AUTOSAR XML (schema 4-2-2)
package /ComponentTypes
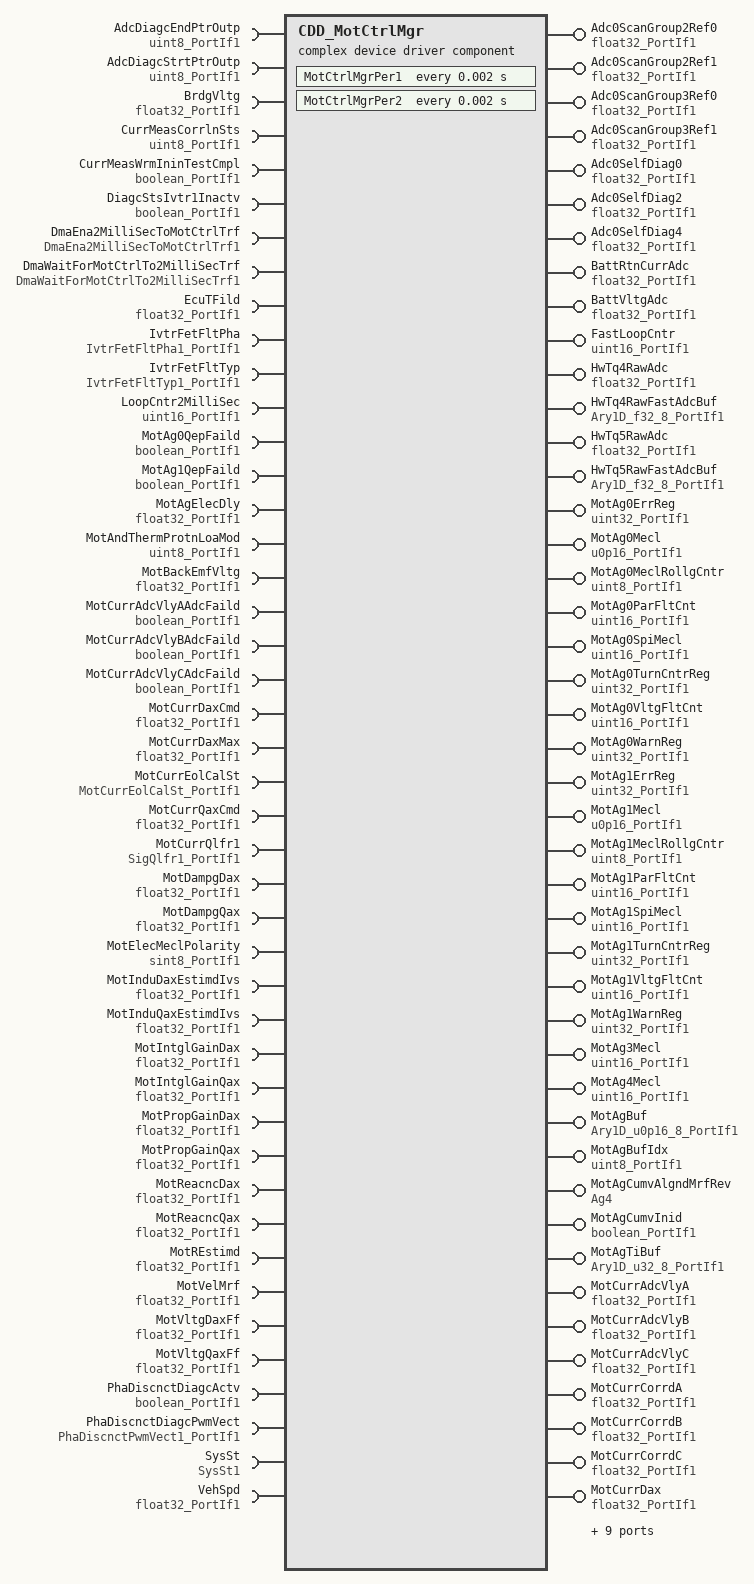
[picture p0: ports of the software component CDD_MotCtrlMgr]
  complex device driver sw component type CDD_MotCtrlMgr
    53 x provide port:
      Adc0ScanGroup2Ref0: nonqueued-sender-com-spec{data-element=Val, init-value=0}, provided-interface=float32_PortIf1
      Adc0ScanGroup2Ref1: nonqueued-sender-com-spec{data-element=Val, init-value=0}, provided-interface=float32_PortIf1
      Adc0ScanGroup3Ref0: nonqueued-sender-com-spec{data-element=Val, init-value=0}, provided-interface=float32_PortIf1
      Adc0ScanGroup3Ref1: nonqueued-sender-com-spec{data-element=Val, init-value=0}, provided-interface=float32_PortIf1
      Adc0SelfDiag0: nonqueued-sender-com-spec{data-element=Val, init-value=0}, provided-interface=float32_PortIf1
      Adc0SelfDiag2: nonqueued-sender-com-spec{data-element=Val, init-value=0}, provided-interface=float32_PortIf1
      Adc0SelfDiag4: nonqueued-sender-com-spec{data-element=Val, init-value=0}, provided-interface=float32_PortIf1
      BattRtnCurrAdc: nonqueued-sender-com-spec{data-element=Val, init-value=0}, provided-interface=float32_PortIf1
      BattVltgAdc: nonqueued-sender-com-spec{data-element=Val, init-value=0}, provided-interface=float32_PortIf1
      FastLoopCntr: nonqueued-sender-com-spec{data-element=Val, init-value=0}, provided-interface=uint16_PortIf1
      HwTq4RawAdc: nonqueued-sender-com-spec{data-element=Val, init-value=0}, provided-interface=float32_PortIf1
      HwTq4RawFastAdcBuf: nonqueued-sender-com-spec{data-element=Ary1D, init-value=8 x 0}, provided-interface=Ary1D_f32_8_PortIf1
      HwTq5RawAdc: nonqueued-sender-com-spec{data-element=Val, init-value=0}, provided-interface=float32_PortIf1
      HwTq5RawFastAdcBuf: nonqueued-sender-com-spec{data-element=Ary1D, init-value=8 x 0}, provided-interface=Ary1D_f32_8_PortIf1
      MotAg0ErrReg: nonqueued-sender-com-spec{data-element=Val, init-value=0}, provided-interface=uint32_PortIf1
      MotAg0Mecl: nonqueued-sender-com-spec{data-element=Val, init-value=0}, provided-interface=u0p16_PortIf1
      MotAg0MeclRollgCntr: nonqueued-sender-com-spec{data-element=Val, init-value=0}, provided-interface=uint8_PortIf1
      MotAg0ParFltCnt: nonqueued-sender-com-spec{data-element=Val, init-value=0}, provided-interface=uint16_PortIf1
      MotAg0SpiMecl: nonqueued-sender-com-spec{data-element=Val, init-value=0}, provided-interface=uint16_PortIf1
      MotAg0TurnCntrReg: nonqueued-sender-com-spec{data-element=Val, init-value=0}, provided-interface=uint32_PortIf1
      MotAg0VltgFltCnt: nonqueued-sender-com-spec{data-element=Val, init-value=0}, provided-interface=uint16_PortIf1
      MotAg0WarnReg: nonqueued-sender-com-spec{data-element=Val, init-value=0}, provided-interface=uint32_PortIf1
      MotAg1ErrReg: nonqueued-sender-com-spec{data-element=Val, init-value=0}, provided-interface=uint32_PortIf1
      MotAg1Mecl: nonqueued-sender-com-spec{data-element=Val, init-value=0}, provided-interface=u0p16_PortIf1
      MotAg1MeclRollgCntr: nonqueued-sender-com-spec{data-element=Val, init-value=0}, provided-interface=uint8_PortIf1
      MotAg1ParFltCnt: nonqueued-sender-com-spec{data-element=Val, init-value=0}, provided-interface=uint16_PortIf1
      MotAg1SpiMecl: nonqueued-sender-com-spec{data-element=Val, init-value=0}, provided-interface=uint16_PortIf1
      MotAg1TurnCntrReg: nonqueued-sender-com-spec{data-element=Val, init-value=0}, provided-interface=uint32_PortIf1
      MotAg1VltgFltCnt: nonqueued-sender-com-spec{data-element=Val, init-value=0}, provided-interface=uint16_PortIf1
      MotAg1WarnReg: nonqueued-sender-com-spec{data-element=Val, init-value=0}, provided-interface=uint32_PortIf1
      MotAg3Mecl: nonqueued-sender-com-spec{data-element=Val, init-value=0}, provided-interface=uint16_PortIf1
      MotAg4Mecl: nonqueued-sender-com-spec{data-element=Val, init-value=0}, provided-interface=uint16_PortIf1
      MotAgBuf: nonqueued-sender-com-spec{data-element=Ary1D, init-value=8 x 0}, provided-interface=Ary1D_u0p16_8_PortIf1
      MotAgBufIdx: nonqueued-sender-com-spec{data-element=Val, init-value=0}, provided-interface=uint8_PortIf1
      MotAgCumvAlgndMrfRev: nonqueued-sender-com-spec{data-element=Val, init-value=0}, provided-interface=Ag4
      MotAgCumvInid: nonqueued-sender-com-spec{data-element=Logl, init-value=0}, provided-interface=boolean_PortIf1
      MotAgTiBuf: nonqueued-sender-com-spec{data-element=Ary1D, init-value=[0, 62, 125, 187, 250, 312, 375, 437]}, provided-interface=Ary1D_u32_8_PortIf1
      MotCurrAdcVlyA: nonqueued-sender-com-spec{data-element=Val, init-value=0}, provided-interface=float32_PortIf1
      MotCurrAdcVlyB: nonqueued-sender-com-spec{data-element=Val, init-value=0}, provided-interface=float32_PortIf1
      MotCurrAdcVlyC: nonqueued-sender-com-spec{data-element=Val, init-value=0}, provided-interface=float32_PortIf1
      MotCurrCorrdA: nonqueued-sender-com-spec{data-element=Val, init-value=0}, provided-interface=float32_PortIf1
      MotCurrCorrdB: nonqueued-sender-com-spec{data-element=Val, init-value=0}, provided-interface=float32_PortIf1
      MotCurrCorrdC: nonqueued-sender-com-spec{data-element=Val, init-value=0}, provided-interface=float32_PortIf1
      MotCurrDax: nonqueued-sender-com-spec{data-element=Val, init-value=0}, provided-interface=float32_PortIf1
      MotCurrQax: nonqueued-sender-com-spec{data-element=Val, init-value=0}, provided-interface=float32_PortIf1
      MotCurrRollgCntr1: nonqueued-sender-com-spec{data-element=Val, init-value=0}, provided-interface=uint8_PortIf1
      MotVltgDax: nonqueued-sender-com-spec{data-element=Val, init-value=0}, provided-interface=float32_PortIf1
      MotVltgQax: nonqueued-sender-com-spec{data-element=Val, init-value=0}, provided-interface=float32_PortIf1
      Ntc5DErrCnt: nonqueued-sender-com-spec{data-element=Val, init-value=0}, provided-interface=uint16_PortIf1
      PhaOnTiSumA: nonqueued-sender-com-spec{data-element=Val, init-value=0}, provided-interface=uint32_PortIf1
      PhaOnTiSumB: nonqueued-sender-com-spec{data-element=Val, init-value=0}, provided-interface=uint32_PortIf1
      PhaOnTiSumC: nonqueued-sender-com-spec{data-element=Val, init-value=0}, provided-interface=uint32_PortIf1
      SlowLoopCntr: nonqueued-sender-com-spec{data-element=Val, init-value=0}, provided-interface=uint16_PortIf1
    44 x require port:
      AdcDiagcEndPtrOutp: nonqueued-receiver-com-spec{data-element=Val, filter=data-filter-type=ALWAYS, init-value=23}, required-interface=uint8_PortIf1
      AdcDiagcStrtPtrOutp: nonqueued-receiver-com-spec{data-element=Val, filter=data-filter-type=ALWAYS, init-value=21}, required-interface=uint8_PortIf1
      BrdgVltg: nonqueued-receiver-com-spec{data-element=Val, filter=data-filter-type=ALWAYS, init-value=6}, required-interface=float32_PortIf1
      CurrMeasCorrlnSts: nonqueued-receiver-com-spec{data-element=Val, filter=data-filter-type=ALWAYS, init-value=0}, required-interface=uint8_PortIf1
      CurrMeasWrmIninTestCmpl: nonqueued-receiver-com-spec{data-element=Logl, filter=data-filter-type=ALWAYS, init-value=0}, required-interface=boolean_PortIf1
      DiagcStsIvtr1Inactv: nonqueued-receiver-com-spec{data-element=Logl, filter=data-filter-type=ALWAYS, init-value=0}, required-interface=boolean_PortIf1
      DmaEna2MilliSecToMotCtrlTrf: client-com-spec=Oper, required-interface=DmaEna2MilliSecToMotCtrlTrf1
      DmaWaitForMotCtrlTo2MilliSecTrf: client-com-spec=Oper, required-interface=DmaWaitForMotCtrlTo2MilliSecTrf1
      EcuTFild: nonqueued-receiver-com-spec{data-element=Val, filter=data-filter-type=ALWAYS, init-value=25}, required-interface=float32_PortIf1
      IvtrFetFltPha: nonqueued-receiver-com-spec{data-element=Val, filter=data-filter-type=ALWAYS, init-value=0}, required-interface=IvtrFetFltPha1_PortIf1
      IvtrFetFltTyp: nonqueued-receiver-com-spec{data-element=Val, filter=data-filter-type=ALWAYS, init-value=0}, required-interface=IvtrFetFltTyp1_PortIf1
      LoopCntr2MilliSec: nonqueued-receiver-com-spec{data-element=Val, filter=data-filter-type=ALWAYS, init-value=0}, required-interface=uint16_PortIf1
      MotAg0QepFaild: nonqueued-receiver-com-spec{data-element=Logl, filter=data-filter-type=ALWAYS, init-value=0}, required-interface=boolean_PortIf1
      MotAg1QepFaild: nonqueued-receiver-com-spec{data-element=Logl, filter=data-filter-type=ALWAYS, init-value=0}, required-interface=boolean_PortIf1
      MotAgElecDly: nonqueued-receiver-com-spec{data-element=Val, filter=data-filter-type=ALWAYS, init-value=0}, required-interface=float32_PortIf1
      MotAndThermProtnLoaMod: nonqueued-receiver-com-spec{data-element=Val, filter=data-filter-type=ALWAYS, init-value=0}, required-interface=uint8_PortIf1
      MotBackEmfVltg: nonqueued-receiver-com-spec{data-element=Val, filter=data-filter-type=ALWAYS, init-value=0}, required-interface=float32_PortIf1
      MotCurrAdcVlyAAdcFaild: nonqueued-receiver-com-spec{data-element=Logl, filter=data-filter-type=ALWAYS, init-value=0}, required-interface=boolean_PortIf1
      MotCurrAdcVlyBAdcFaild: nonqueued-receiver-com-spec{data-element=Logl, filter=data-filter-type=ALWAYS, init-value=0}, required-interface=boolean_PortIf1
      MotCurrAdcVlyCAdcFaild: nonqueued-receiver-com-spec{data-element=Logl, filter=data-filter-type=ALWAYS, init-value=0}, required-interface=boolean_PortIf1
      MotCurrDaxCmd: nonqueued-receiver-com-spec{data-element=Val, filter=data-filter-type=ALWAYS, init-value=0}, required-interface=float32_PortIf1
      MotCurrDaxMax: nonqueued-receiver-com-spec{data-element=Val, filter=data-filter-type=ALWAYS, init-value=0}, required-interface=float32_PortIf1
      MotCurrEolCalSt: nonqueued-receiver-com-spec{data-element=Val, filter=data-filter-type=ALWAYS, init-value=0}, required-interface=MotCurrEolCalSt_PortIf1
      MotCurrQaxCmd: nonqueued-receiver-com-spec{data-element=Val, filter=data-filter-type=ALWAYS, init-value=0}, required-interface=float32_PortIf1
      MotCurrQlfr1: nonqueued-receiver-com-spec{data-element=Val, filter=data-filter-type=ALWAYS, init-value=0}, required-interface=SigQlfr1_PortIf1
      MotDampgDax: nonqueued-receiver-com-spec{data-element=Val, filter=data-filter-type=ALWAYS, init-value=0}, required-interface=float32_PortIf1
      MotDampgQax: nonqueued-receiver-com-spec{data-element=Val, filter=data-filter-type=ALWAYS, init-value=0}, required-interface=float32_PortIf1
      MotElecMeclPolarity: nonqueued-receiver-com-spec{data-element=Val, filter=data-filter-type=ALWAYS, init-value=1}, required-interface=sint8_PortIf1
      MotInduDaxEstimdIvs: nonqueued-receiver-com-spec{data-element=Val, filter=data-filter-type=ALWAYS, init-value=0}, required-interface=float32_PortIf1
      MotInduQaxEstimdIvs: nonqueued-receiver-com-spec{data-element=Val, filter=data-filter-type=ALWAYS, init-value=0}, required-interface=float32_PortIf1
      MotIntglGainDax: nonqueued-receiver-com-spec{data-element=Val, filter=data-filter-type=ALWAYS, init-value=0}, required-interface=float32_PortIf1
      MotIntglGainQax: nonqueued-receiver-com-spec{data-element=Val, filter=data-filter-type=ALWAYS, init-value=0}, required-interface=float32_PortIf1
      MotPropGainDax: nonqueued-receiver-com-spec{data-element=Val, filter=data-filter-type=ALWAYS, init-value=0}, required-interface=float32_PortIf1
      MotPropGainQax: nonqueued-receiver-com-spec{data-element=Val, filter=data-filter-type=ALWAYS, init-value=0}, required-interface=float32_PortIf1
      MotReacncDax: nonqueued-receiver-com-spec{data-element=Val, filter=data-filter-type=ALWAYS, init-value=0}, required-interface=float32_PortIf1
      MotReacncQax: nonqueued-receiver-com-spec{data-element=Val, filter=data-filter-type=ALWAYS, init-value=0}, required-interface=float32_PortIf1
      MotREstimd: nonqueued-receiver-com-spec{data-element=Val, filter=data-filter-type=ALWAYS, init-value=0.0139083}, required-interface=float32_PortIf1
      MotVelMrf: nonqueued-receiver-com-spec{data-element=Val, filter=data-filter-type=ALWAYS, init-value=0}, required-interface=float32_PortIf1
      MotVltgDaxFf: nonqueued-receiver-com-spec{data-element=Val, filter=data-filter-type=ALWAYS, init-value=0}, required-interface=float32_PortIf1
      MotVltgQaxFf: nonqueued-receiver-com-spec{data-element=Val, filter=data-filter-type=ALWAYS, init-value=0}, required-interface=float32_PortIf1
      PhaDiscnctDiagcActv: nonqueued-receiver-com-spec{data-element=Logl, filter=data-filter-type=ALWAYS, init-value=0}, required-interface=boolean_PortIf1
      PhaDiscnctDiagcPwmVect: nonqueued-receiver-com-spec{data-element=Val, filter=data-filter-type=ALWAYS, init-value=0}, required-interface=PhaDiscnctPwmVect1_PortIf1
      SysSt: nonqueued-receiver-com-spec{data-element=Val, filter=data-filter-type=ALWAYS, init-value=3}, required-interface=SysSt1
      VehSpd: nonqueued-receiver-com-spec{data-element=Val, filter=data-filter-type=ALWAYS, init-value=0}, required-interface=float32_PortIf1
    behavior CDD_MotCtrlMgr_InternalBehavior: data-type-mapping=Nexteer
      timing event TMT_MotCtrlMgrPer1: start-on-event=MotCtrlMgrPer1, period=0.002
      timing event TMT_MotCtrlMgrPer2: start-on-event=MotCtrlMgrPer2, period=0.002
      port-api-options:
        enable-take-address=false, error-handling=NO-TRANSFORMER-ERROR-HANDLING, indirect-api=false, port=Adc0ScanGroup2Ref0
        enable-take-address=false, error-handling=NO-TRANSFORMER-ERROR-HANDLING, indirect-api=false, port=Adc0ScanGroup2Ref1
        enable-take-address=false, error-handling=NO-TRANSFORMER-ERROR-HANDLING, indirect-api=false, port=Adc0ScanGroup3Ref0
        enable-take-address=false, error-handling=NO-TRANSFORMER-ERROR-HANDLING, indirect-api=false, port=Adc0ScanGroup3Ref1
        enable-take-address=false, error-handling=NO-TRANSFORMER-ERROR-HANDLING, indirect-api=false, port=Adc0SelfDiag0
        enable-take-address=false, error-handling=NO-TRANSFORMER-ERROR-HANDLING, indirect-api=false, port=Adc0SelfDiag2
        enable-take-address=false, error-handling=NO-TRANSFORMER-ERROR-HANDLING, indirect-api=false, port=Adc0SelfDiag4
        enable-take-address=false, error-handling=NO-TRANSFORMER-ERROR-HANDLING, indirect-api=false, port=AdcDiagcEndPtrOutp
        enable-take-address=false, error-handling=NO-TRANSFORMER-ERROR-HANDLING, indirect-api=false, port=AdcDiagcStrtPtrOutp
        enable-take-address=false, error-handling=NO-TRANSFORMER-ERROR-HANDLING, indirect-api=false, port=BattRtnCurrAdc
        enable-take-address=false, error-handling=NO-TRANSFORMER-ERROR-HANDLING, indirect-api=false, port=BattVltgAdc
        enable-take-address=false, error-handling=NO-TRANSFORMER-ERROR-HANDLING, indirect-api=false, port=BrdgVltg
        enable-take-address=false, error-handling=NO-TRANSFORMER-ERROR-HANDLING, indirect-api=false, port=CurrMeasCorrlnSts
        enable-take-address=false, error-handling=NO-TRANSFORMER-ERROR-HANDLING, indirect-api=false, port=CurrMeasWrmIninTestCmpl
        enable-take-address=false, error-handling=NO-TRANSFORMER-ERROR-HANDLING, indirect-api=false, port=DiagcStsIvtr1Inactv
        enable-take-address=false, error-handling=NO-TRANSFORMER-ERROR-HANDLING, indirect-api=false, port=DmaEna2MilliSecToMotCtrlTrf
        enable-take-address=false, error-handling=NO-TRANSFORMER-ERROR-HANDLING, indirect-api=false, port=DmaWaitForMotCtrlTo2MilliSecTrf
        enable-take-address=false, error-handling=NO-TRANSFORMER-ERROR-HANDLING, indirect-api=false, port=EcuTFild
        enable-take-address=false, error-handling=NO-TRANSFORMER-ERROR-HANDLING, indirect-api=false, port=FastLoopCntr
        enable-take-address=false, error-handling=NO-TRANSFORMER-ERROR-HANDLING, indirect-api=false, port=HwTq4RawAdc
        enable-take-address=false, error-handling=NO-TRANSFORMER-ERROR-HANDLING, indirect-api=false, port=HwTq4RawFastAdcBuf
        enable-take-address=false, error-handling=NO-TRANSFORMER-ERROR-HANDLING, indirect-api=false, port=HwTq5RawAdc
        enable-take-address=false, error-handling=NO-TRANSFORMER-ERROR-HANDLING, indirect-api=false, port=HwTq5RawFastAdcBuf
        enable-take-address=false, error-handling=NO-TRANSFORMER-ERROR-HANDLING, indirect-api=false, port=IvtrFetFltPha
        enable-take-address=false, error-handling=NO-TRANSFORMER-ERROR-HANDLING, indirect-api=false, port=IvtrFetFltTyp
        enable-take-address=false, error-handling=NO-TRANSFORMER-ERROR-HANDLING, indirect-api=false, port=LoopCntr2MilliSec
        enable-take-address=false, error-handling=NO-TRANSFORMER-ERROR-HANDLING, indirect-api=false, port=MotAg0ErrReg
        enable-take-address=false, error-handling=NO-TRANSFORMER-ERROR-HANDLING, indirect-api=false, port=MotAg0Mecl
        enable-take-address=false, error-handling=NO-TRANSFORMER-ERROR-HANDLING, indirect-api=false, port=MotAg0MeclRollgCntr
        enable-take-address=false, error-handling=NO-TRANSFORMER-ERROR-HANDLING, indirect-api=false, port=MotAg0ParFltCnt
        enable-take-address=false, error-handling=NO-TRANSFORMER-ERROR-HANDLING, indirect-api=false, port=MotAg0QepFaild
        enable-take-address=false, error-handling=NO-TRANSFORMER-ERROR-HANDLING, indirect-api=false, port=MotAg0SpiMecl
        enable-take-address=false, error-handling=NO-TRANSFORMER-ERROR-HANDLING, indirect-api=false, port=MotAg0TurnCntrReg
        enable-take-address=false, error-handling=NO-TRANSFORMER-ERROR-HANDLING, indirect-api=false, port=MotAg0VltgFltCnt
        enable-take-address=false, error-handling=NO-TRANSFORMER-ERROR-HANDLING, indirect-api=false, port=MotAg0WarnReg
        enable-take-address=false, error-handling=NO-TRANSFORMER-ERROR-HANDLING, indirect-api=false, port=MotAg1ErrReg
        enable-take-address=false, error-handling=NO-TRANSFORMER-ERROR-HANDLING, indirect-api=false, port=MotAg1Mecl
        enable-take-address=false, error-handling=NO-TRANSFORMER-ERROR-HANDLING, indirect-api=false, port=MotAg1MeclRollgCntr
        enable-take-address=false, error-handling=NO-TRANSFORMER-ERROR-HANDLING, indirect-api=false, port=MotAg1ParFltCnt
        enable-take-address=false, error-handling=NO-TRANSFORMER-ERROR-HANDLING, indirect-api=false, port=MotAg1QepFaild
        enable-take-address=false, error-handling=NO-TRANSFORMER-ERROR-HANDLING, indirect-api=false, port=MotAg1SpiMecl
        enable-take-address=false, error-handling=NO-TRANSFORMER-ERROR-HANDLING, indirect-api=false, port=MotAg1TurnCntrReg
        enable-take-address=false, error-handling=NO-TRANSFORMER-ERROR-HANDLING, indirect-api=false, port=MotAg1VltgFltCnt
        enable-take-address=false, error-handling=NO-TRANSFORMER-ERROR-HANDLING, indirect-api=false, port=MotAg1WarnReg
        enable-take-address=false, error-handling=NO-TRANSFORMER-ERROR-HANDLING, indirect-api=false, port=MotAg3Mecl
        enable-take-address=false, error-handling=NO-TRANSFORMER-ERROR-HANDLING, indirect-api=false, port=MotAg4Mecl
        enable-take-address=false, error-handling=NO-TRANSFORMER-ERROR-HANDLING, indirect-api=false, port=MotAgBuf
        enable-take-address=false, error-handling=NO-TRANSFORMER-ERROR-HANDLING, indirect-api=false, port=MotAgBufIdx
        enable-take-address=false, error-handling=NO-TRANSFORMER-ERROR-HANDLING, indirect-api=false, port=MotAgCumvAlgndMrfRev
        enable-take-address=false, error-handling=NO-TRANSFORMER-ERROR-HANDLING, indirect-api=false, port=MotAgCumvInid
        enable-take-address=false, error-handling=NO-TRANSFORMER-ERROR-HANDLING, indirect-api=false, port=MotAgElecDly
        enable-take-address=false, error-handling=NO-TRANSFORMER-ERROR-HANDLING, indirect-api=false, port=MotAgTiBuf
        enable-take-address=false, error-handling=NO-TRANSFORMER-ERROR-HANDLING, indirect-api=false, port=MotAndThermProtnLoaMod
        enable-take-address=false, error-handling=NO-TRANSFORMER-ERROR-HANDLING, indirect-api=false, port=MotBackEmfVltg
        enable-take-address=false, error-handling=NO-TRANSFORMER-ERROR-HANDLING, indirect-api=false, port=MotCurrAdcVlyA
        enable-take-address=false, error-handling=NO-TRANSFORMER-ERROR-HANDLING, indirect-api=false, port=MotCurrAdcVlyAAdcFaild
        enable-take-address=false, error-handling=NO-TRANSFORMER-ERROR-HANDLING, indirect-api=false, port=MotCurrAdcVlyB
        enable-take-address=false, error-handling=NO-TRANSFORMER-ERROR-HANDLING, indirect-api=false, port=MotCurrAdcVlyBAdcFaild
        enable-take-address=false, error-handling=NO-TRANSFORMER-ERROR-HANDLING, indirect-api=false, port=MotCurrAdcVlyC
        enable-take-address=false, error-handling=NO-TRANSFORMER-ERROR-HANDLING, indirect-api=false, port=MotCurrAdcVlyCAdcFaild
        enable-take-address=false, error-handling=NO-TRANSFORMER-ERROR-HANDLING, indirect-api=false, port=MotCurrCorrdA
        enable-take-address=false, error-handling=NO-TRANSFORMER-ERROR-HANDLING, indirect-api=false, port=MotCurrCorrdB
        enable-take-address=false, error-handling=NO-TRANSFORMER-ERROR-HANDLING, indirect-api=false, port=MotCurrCorrdC
        enable-take-address=false, error-handling=NO-TRANSFORMER-ERROR-HANDLING, indirect-api=false, port=MotCurrDax
        enable-take-address=false, error-handling=NO-TRANSFORMER-ERROR-HANDLING, indirect-api=false, port=MotCurrDaxCmd
        enable-take-address=false, error-handling=NO-TRANSFORMER-ERROR-HANDLING, indirect-api=false, port=MotCurrDaxMax
        enable-take-address=false, error-handling=NO-TRANSFORMER-ERROR-HANDLING, indirect-api=false, port=MotCurrEolCalSt
        enable-take-address=false, error-handling=NO-TRANSFORMER-ERROR-HANDLING, indirect-api=false, port=MotCurrQax
        enable-take-address=false, error-handling=NO-TRANSFORMER-ERROR-HANDLING, indirect-api=false, port=MotCurrQaxCmd
        enable-take-address=false, error-handling=NO-TRANSFORMER-ERROR-HANDLING, indirect-api=false, port=MotCurrQlfr1
        enable-take-address=false, error-handling=NO-TRANSFORMER-ERROR-HANDLING, indirect-api=false, port=MotCurrRollgCntr1
        enable-take-address=false, error-handling=NO-TRANSFORMER-ERROR-HANDLING, indirect-api=false, port=MotDampgDax
        enable-take-address=false, error-handling=NO-TRANSFORMER-ERROR-HANDLING, indirect-api=false, port=MotDampgQax
        enable-take-address=false, error-handling=NO-TRANSFORMER-ERROR-HANDLING, indirect-api=false, port=MotElecMeclPolarity
        enable-take-address=false, error-handling=NO-TRANSFORMER-ERROR-HANDLING, indirect-api=false, port=MotInduDaxEstimdIvs
        enable-take-address=false, error-handling=NO-TRANSFORMER-ERROR-HANDLING, indirect-api=false, port=MotInduQaxEstimdIvs
        enable-take-address=false, error-handling=NO-TRANSFORMER-ERROR-HANDLING, indirect-api=false, port=MotIntglGainDax
        enable-take-address=false, error-handling=NO-TRANSFORMER-ERROR-HANDLING, indirect-api=false, port=MotIntglGainQax
        enable-take-address=false, error-handling=NO-TRANSFORMER-ERROR-HANDLING, indirect-api=false, port=MotPropGainDax
        enable-take-address=false, error-handling=NO-TRANSFORMER-ERROR-HANDLING, indirect-api=false, port=MotPropGainQax
        enable-take-address=false, error-handling=NO-TRANSFORMER-ERROR-HANDLING, indirect-api=false, port=MotReacncDax
        enable-take-address=false, error-handling=NO-TRANSFORMER-ERROR-HANDLING, indirect-api=false, port=MotReacncQax
        enable-take-address=false, error-handling=NO-TRANSFORMER-ERROR-HANDLING, indirect-api=false, port=MotREstimd
        enable-take-address=false, error-handling=NO-TRANSFORMER-ERROR-HANDLING, indirect-api=false, port=MotVelMrf
        enable-take-address=false, error-handling=NO-TRANSFORMER-ERROR-HANDLING, indirect-api=false, port=MotVltgDax
        enable-take-address=false, error-handling=NO-TRANSFORMER-ERROR-HANDLING, indirect-api=false, port=MotVltgDaxFf
        enable-take-address=false, error-handling=NO-TRANSFORMER-ERROR-HANDLING, indirect-api=false, port=MotVltgQax
        enable-take-address=false, error-handling=NO-TRANSFORMER-ERROR-HANDLING, indirect-api=false, port=MotVltgQaxFf
        enable-take-address=false, error-handling=NO-TRANSFORMER-ERROR-HANDLING, indirect-api=false, port=Ntc5DErrCnt
        enable-take-address=false, error-handling=NO-TRANSFORMER-ERROR-HANDLING, indirect-api=false, port=PhaDiscnctDiagcActv
        enable-take-address=false, error-handling=NO-TRANSFORMER-ERROR-HANDLING, indirect-api=false, port=PhaDiscnctDiagcPwmVect
        enable-take-address=false, error-handling=NO-TRANSFORMER-ERROR-HANDLING, indirect-api=false, port=PhaOnTiSumA
        enable-take-address=false, error-handling=NO-TRANSFORMER-ERROR-HANDLING, indirect-api=false, port=PhaOnTiSumB
        enable-take-address=false, error-handling=NO-TRANSFORMER-ERROR-HANDLING, indirect-api=false, port=PhaOnTiSumC
        enable-take-address=false, error-handling=NO-TRANSFORMER-ERROR-HANDLING, indirect-api=false, port=SlowLoopCntr
        enable-take-address=false, error-handling=NO-TRANSFORMER-ERROR-HANDLING, indirect-api=false, port=SysSt
        enable-take-address=false, error-handling=NO-TRANSFORMER-ERROR-HANDLING, indirect-api=false, port=VehSpd
      runnable MotCtrlMgrPer1
        data-receive-point-by-arguments:
          access SEND_MotAndThermProtnLoaMod_Val: accessed-variable=MotAndThermProtnLoaMod.Val
        data-send-points:
          53 x access:
            SEND_Adc0ScanGroup2Ref0_Val: accessed-variable=Adc0ScanGroup2Ref0.Val
            SEND_Adc0ScanGroup2Ref1_Val: accessed-variable=Adc0ScanGroup2Ref1.Val
            SEND_Adc0ScanGroup3Ref0_Val: accessed-variable=Adc0ScanGroup3Ref0.Val
            SEND_Adc0ScanGroup3Ref1_Val: accessed-variable=Adc0ScanGroup3Ref1.Val
            SEND_Adc0SelfDiag0_Val: accessed-variable=Adc0SelfDiag0.Val
            SEND_Adc0SelfDiag2_Val: accessed-variable=Adc0SelfDiag2.Val
            SEND_Adc0SelfDiag4_Val: accessed-variable=Adc0SelfDiag4.Val
            SEND_BattRtnCurrAdc_Val: accessed-variable=BattRtnCurrAdc.Val
            SEND_BattVltgAdc_Val: accessed-variable=BattVltgAdc.Val
            SEND_FastLoopCntr_Val: accessed-variable=FastLoopCntr.Val
            SEND_HwTq4RawAdc_Val: accessed-variable=HwTq4RawAdc.Val
            SEND_HwTq4RawFastAdcBuf_Ary1D: accessed-variable=HwTq4RawFastAdcBuf.Ary1D
            SEND_HwTq5RawAdc_Val: accessed-variable=HwTq5RawAdc.Val
            SEND_HwTq5RawFastAdcBuf_Ary1D: accessed-variable=HwTq5RawFastAdcBuf.Ary1D
            SEND_MotAg0ErrReg_Val: accessed-variable=MotAg0ErrReg.Val
            SEND_MotAg0Mecl_Val: accessed-variable=MotAg0Mecl.Val
            SEND_MotAg0MeclRollgCntr_Val: accessed-variable=MotAg0MeclRollgCntr.Val
            SEND_MotAg0ParFltCnt_Val: accessed-variable=MotAg0ParFltCnt.Val
            SEND_MotAg0SpiMecl_Val: accessed-variable=MotAg0SpiMecl.Val
            SEND_MotAg0TurnCntrReg_Val: accessed-variable=MotAg0TurnCntrReg.Val
            SEND_MotAg0VltgFltCnt_Val: accessed-variable=MotAg0VltgFltCnt.Val
            SEND_MotAg0WarnReg_Val: accessed-variable=MotAg0WarnReg.Val
            SEND_MotAg1ErrReg_Val: accessed-variable=MotAg1ErrReg.Val
            SEND_MotAg1Mecl_Val: accessed-variable=MotAg1Mecl.Val
            SEND_MotAg1MeclRollgCntr_Val: accessed-variable=MotAg1MeclRollgCntr.Val
            SEND_MotAg1ParFltCnt_Val: accessed-variable=MotAg1ParFltCnt.Val
            SEND_MotAg1SpiMecl_Val: accessed-variable=MotAg1SpiMecl.Val
            SEND_MotAg1TurnCntrReg_Val: accessed-variable=MotAg1TurnCntrReg.Val
            SEND_MotAg1VltgFltCnt_Val: accessed-variable=MotAg1VltgFltCnt.Val
            SEND_MotAg1WarnReg_Val: accessed-variable=MotAg1WarnReg.Val
            SEND_MotAg3Mecl_Val: accessed-variable=MotAg3Mecl.Val
            SEND_MotAg4Mecl_Val: accessed-variable=MotAg4Mecl.Val
            SEND_MotAgBuf_Ary1D: accessed-variable=MotAgBuf.Ary1D
            SEND_MotAgBufIdx_Val: accessed-variable=MotAgBufIdx.Val
            SEND_MotAgCumvAlgndMrfRev_Val: accessed-variable=MotAgCumvAlgndMrfRev.Val
            SEND_MotAgCumvInid_Logl: accessed-variable=MotAgCumvInid.Logl
            SEND_MotAgTiBuf_Ary1D: accessed-variable=MotAgTiBuf.Ary1D
            SEND_MotCurrAdcVlyA_Val: accessed-variable=MotCurrAdcVlyA.Val
            SEND_MotCurrAdcVlyB_Val: accessed-variable=MotCurrAdcVlyB.Val
            SEND_MotCurrAdcVlyC_Val: accessed-variable=MotCurrAdcVlyC.Val
            SEND_MotCurrCorrdA_Val: accessed-variable=MotCurrCorrdA.Val
            SEND_MotCurrCorrdB_Val: accessed-variable=MotCurrCorrdB.Val
            SEND_MotCurrCorrdC_Val: accessed-variable=MotCurrCorrdC.Val
            SEND_MotCurrDax_Val: accessed-variable=MotCurrDax.Val
            SEND_MotCurrQax_Val: accessed-variable=MotCurrQax.Val
            SEND_MotCurrRollgCntr1_Val: accessed-variable=MotCurrRollgCntr1.Val
            SEND_MotVltgDax_Val: accessed-variable=MotVltgDax.Val
            SEND_MotVltgQax_Val: accessed-variable=MotVltgQax.Val
            SEND_Ntc5DErrCnt_Val: accessed-variable=Ntc5DErrCnt.Val
            SEND_PhaOnTiSumA_Val: accessed-variable=PhaOnTiSumA.Val
            SEND_PhaOnTiSumB_Val: accessed-variable=PhaOnTiSumB.Val
            SEND_PhaOnTiSumC_Val: accessed-variable=PhaOnTiSumC.Val
            SEND_SlowLoopCntr_Val: accessed-variable=SlowLoopCntr.Val
        sync call SC_DmaWaitForMotCtrlTo2MilliSecTrf_Oper: operation=DmaWaitForMotCtrlTo2MilliSecTrf.Oper, timeout=0
      runnable MotCtrlMgrPer2
        data-receive-point-by-arguments:
          42 x access:
            REC_AdcDiagcEndPtrOutp_Val: accessed-variable=AdcDiagcEndPtrOutp.Val
            REC_AdcDiagcStrtPtrOutp_Val: accessed-variable=AdcDiagcStrtPtrOutp.Val
            REC_BrdgVltg_Val: accessed-variable=BrdgVltg.Val
            REC_CurrMeasCorrlnSts_Val: accessed-variable=CurrMeasCorrlnSts.Val
            REC_CurrMeasWrmIninTestCmpl_Logl: accessed-variable=CurrMeasWrmIninTestCmpl.Logl
            REC_DiagcStsIvtr1Inactv_Logl: accessed-variable=DiagcStsIvtr1Inactv.Logl
            REC_EcuTFild_Val: accessed-variable=EcuTFild.Val
            REC_IvtrFetFltPha_Val: accessed-variable=IvtrFetFltPha.Val
            REC_IvtrFetFltTyp_Val: accessed-variable=IvtrFetFltTyp.Val
            REC_LoopCntr2MilliSec_Val: accessed-variable=LoopCntr2MilliSec.Val
            REC_MotAg0QepFaild_Logl: accessed-variable=MotAg0QepFaild.Logl
            REC_MotAg1QepFaild_Logl: accessed-variable=MotAg1QepFaild.Logl
            REC_MotAgElecDly_Val: accessed-variable=MotAgElecDly.Val
            REC_MotAndThermProtnLoaMod_Val: accessed-variable=MotAndThermProtnLoaMod.Val
            REC_MotBackEmfVltg_Val: accessed-variable=MotBackEmfVltg.Val
            REC_MotCurrAdcVlyAAdcFaild_Logl: accessed-variable=MotCurrAdcVlyAAdcFaild.Logl
            REC_MotCurrAdcVlyBAdcFaild_Logl: accessed-variable=MotCurrAdcVlyBAdcFaild.Logl
            REC_MotCurrAdcVlyCAdcFaild_Logl: accessed-variable=MotCurrAdcVlyCAdcFaild.Logl
            REC_MotCurrDaxCmd_Val: accessed-variable=MotCurrDaxCmd.Val
            REC_MotCurrDaxMax_Val: accessed-variable=MotCurrDaxMax.Val
            REC_MotCurrEolCalSt_Val: accessed-variable=MotCurrEolCalSt.Val
            REC_MotCurrQaxCmd_Val: accessed-variable=MotCurrQaxCmd.Val
            REC_MotCurrQlfr1_Val: accessed-variable=MotCurrQlfr1.Val
            REC_MotDampgDax_Val: accessed-variable=MotDampgDax.Val
            REC_MotDampgQax_Val: accessed-variable=MotDampgQax.Val
            REC_MotElecMeclPolarity_Val: accessed-variable=MotElecMeclPolarity.Val
            REC_MotInduDaxEstimdIvs_Val: accessed-variable=MotInduDaxEstimdIvs.Val
            REC_MotInduQaxEstimdIvs_Val: accessed-variable=MotInduQaxEstimdIvs.Val
            REC_MotIntglGainDax_Val: accessed-variable=MotIntglGainDax.Val
            REC_MotIntglGainQax_Val: accessed-variable=MotIntglGainQax.Val
            REC_MotPropGainDax_Val: accessed-variable=MotPropGainDax.Val
            REC_MotPropGainQax_Val: accessed-variable=MotPropGainQax.Val
            REC_MotReacncDax_Val: accessed-variable=MotReacncDax.Val
            REC_MotReacncQax_Val: accessed-variable=MotReacncQax.Val
            REC_MotREstimd_Val: accessed-variable=MotREstimd.Val
            REC_MotVelMrf_Val: accessed-variable=MotVelMrf.Val
            REC_MotVltgDaxFf_Val: accessed-variable=MotVltgDaxFf.Val
            REC_MotVltgQaxFf_Val: accessed-variable=MotVltgQaxFf.Val
            REC_PhaDiscnctDiagcActv_Logl: accessed-variable=PhaDiscnctDiagcActv.Logl
            REC_PhaDiscnctDiagcPwmVect_Val: accessed-variable=PhaDiscnctDiagcPwmVect.Val
            REC_SysSt_Val: accessed-variable=SysSt.Val
            REC_VehSpd_Val: accessed-variable=VehSpd.Val
        sync call SC_DmaEna2MilliSecToMotCtrlTrf_Oper: operation=DmaEna2MilliSecToMotCtrlTrf.Oper, timeout=0
  swc implementation CDD_MotCtrlMgr_Implementation: behavior=CDD_MotCtrlMgr_InternalBehavior
    code-descriptors:
      code Default: artifact-descriptors=autosar-engineering-object={short-label=Default, category=SWSRC}
